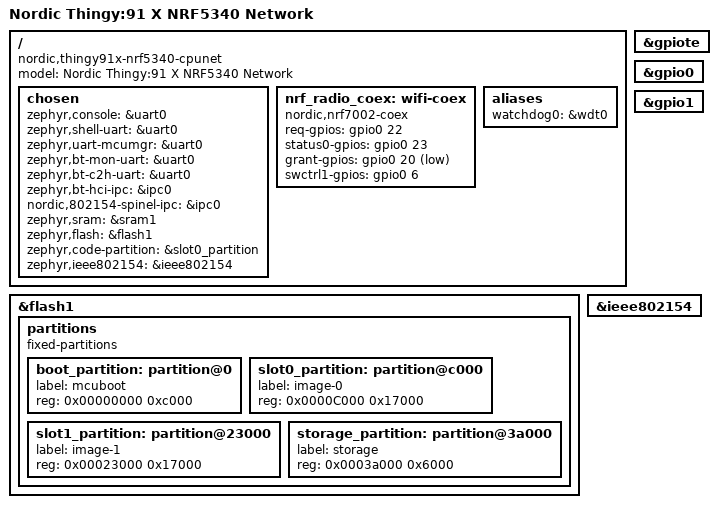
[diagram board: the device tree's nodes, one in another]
/*
 * Copyright (c) 2024 Nordic Semiconductor
 * SPDX-License-Identifier: LicenseRef-Nordic-5-Clause
 */

/dts-v1/;
#include <nordic/nrf5340_cpunet_qkaa.dtsi>

/ {
	model = "Nordic Thingy:91 X NRF5340 Network";
	compatible = "nordic,thingy91x-nrf5340-cpunet";

	chosen {
		zephyr,console = &uart0;
		zephyr,shell-uart = &uart0;
		zephyr,uart-mcumgr = &uart0;
		zephyr,bt-mon-uart = &uart0;
		zephyr,bt-c2h-uart = &uart0;
		zephyr,bt-hci-ipc = &ipc0;
		nordic,802154-spinel-ipc = &ipc0;
		zephyr,sram = &sram1;
		zephyr,flash = &flash1;
		zephyr,code-partition = &slot0_partition;
		zephyr,ieee802154 = &ieee802154;
	};

	nrf_radio_coex: wifi-coex {
		status = "okay";
		compatible = "nordic,nrf7002-coex";
		req-gpios = <&gpio0 22 GPIO_ACTIVE_HIGH>;
		status0-gpios = <&gpio0 23 GPIO_ACTIVE_HIGH>;
		grant-gpios = <&gpio0 20 (GPIO_PULL_DOWN | GPIO_ACTIVE_LOW)>;
		swctrl1-gpios = <&gpio0 6 GPIO_ACTIVE_HIGH>;
	};

	/* These aliases are provided for compatibility with samples */
	aliases {
		watchdog0 = &wdt0;
	};
};

&gpiote {
	status = "okay";
};

&gpio0 {
	status = "okay";
};

&gpio1 {
	status = "okay";
};

&flash1 {

	partitions {
		compatible = "fixed-partitions";
		#address-cells = <1>;
		#size-cells = <1>;

		boot_partition: partition@0 {
			label = "mcuboot";
			reg = <0x00000000 0xc000>;
		};
		slot0_partition: partition@c000 {
			label = "image-0";
			reg = <0x0000C000 0x17000>;
		};
		slot1_partition: partition@23000 {
			label = "image-1";
			reg = <0x00023000 0x17000>;
		};
		storage_partition: partition@3a000 {
			label = "storage";
			reg = <0x0003a000 0x6000>;
		};
	};
};

&ieee802154 {
	status = "okay";
};

/* Include shared RAM configuration file */
#include "nrf5340_shared_sram_planning_conf.dts"
